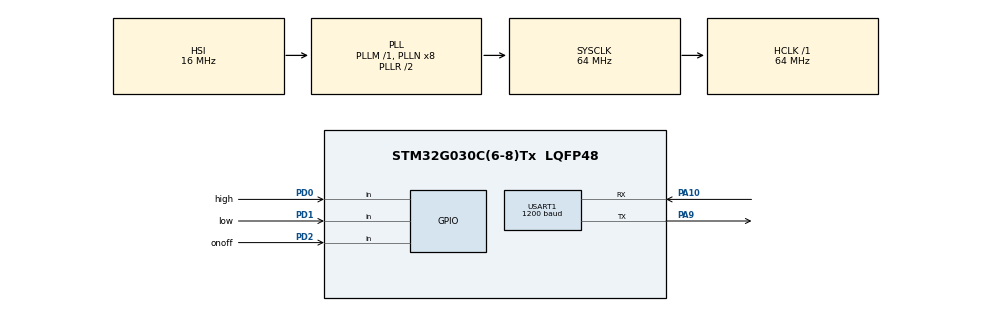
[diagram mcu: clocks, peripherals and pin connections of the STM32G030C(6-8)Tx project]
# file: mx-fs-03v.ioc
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Mcu.Family=STM32G0
Mcu.Name=STM32G030C(6-8)Tx
Mcu.Package=LQFP48
PA10.Mode=Asynchronous
PA10.Signal=USART1_RX
PA13.Mode=Serial_Wire
PA13.Signal=SYS_SWDIO
PA14-BOOT0.Mode=Serial_Wire
PA14-BOOT0.Signal=SYS_SWCLK
PA9.GPIO_Speed=GPIO_SPEED_FREQ_HIGH
PA9.Mode=Asynchronous
PA9.Signal=USART1_TX
PD0.GPIO_Label=high
PD0.GPIO_PuPd=GPIO_PULLUP
PD0.Signal=GPIO_Input
PD1.GPIO_Label=low
PD1.GPIO_PuPd=GPIO_PULLUP
PD1.Signal=GPIO_Input
PD2.GPIO_Label=onoff
PD2.GPIO_PuPd=GPIO_PULLUP
PD2.Signal=GPIO_Input
PF0-OSC_IN\ (PF0).Mode=HSE-External-Oscillator
PF0-OSC_IN\ (PF0).Signal=RCC_OSC_IN
PF1-OSC_OUT\ (PF1).Mode=HSE-External-Oscillator
PF1-OSC_OUT\ (PF1).Signal=RCC_OSC_OUT
ProjectManager.HeapSize=0x200
ProjectManager.StackSize=0x400
ProjectManager.TargetToolchain=MDK-ARM V5.32
RCC.ADCFreq_Value=64000000
RCC.AHBFreq_Value=64000000
RCC.CortexFreq_Value=64000000
RCC.EXTERNAL_CLOCK_VALUE=12288000
RCC.HCLKFreq_Value=64000000
RCC.HSE_VALUE=8000000
RCC.HSI_VALUE=16000000
RCC.LSE_VALUE=32768
RCC.SYSCLKFreq_VALUE=64000000
RCC.SYSCLKSource=RCC_SYSCLKSOURCE_PLLCLK
RCC.VCOOutputFreq_Value=128000000
TIM1.AutoReloadPreload=TIM_AUTORELOAD_PRELOAD_DISABLE
TIM1.Period=999
TIM1.Prescaler=31
USART1.BaudRate=1200
USART1.OneBitSampling=UART_ONE_BIT_SAMPLE_ENABLE
USART1.VirtualMode-Asynchronous=VM_ASYNC
VP_TIM1_VS_ClockSourceINT.Mode=Internal
board=custom

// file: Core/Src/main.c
/* USER CODE BEGIN Header */
/**
  ******************************************************************************
  * @file           : main.c
  * @brief          : Main program body
  ******************************************************************************
  * @attention
  *
  * Copyright (c) 2024 STMicroelectronics.
  * All rights reserved.
  *
  * This software is licensed under terms that can be found in the LICENSE file
  * in the root directory of this software component.
  * If no LICENSE file comes with this software, it is provided AS-IS.
  *
  ******************************************************************************
  */
/* USER CODE END Header */
#include "main.h"

 TIM_HandleTypeDef htim1;

 UART_HandleTypeDef huart1;

void SystemClock_Config(void);
static void MX_GPIO_Init(void);
static void MX_TIM1_Init(void);
static void MX_USART1_UART_Init(void);
/* USER CODE BEGIN PFP */
void send_command(uint8_t command);
/* USER CODE END PFP */

int main(void)
{

  /* MCU Configuration--------------------------------------------------------*/

  /* Reset of all peripherals, Initializes the Flash interface and the Systick. */
  HAL_Init();

  /* Configure the system clock */
  SystemClock_Config();

  /* Initialize all configured peripherals */
  MX_GPIO_Init();
  MX_TIM1_Init();
  MX_USART1_UART_Init();
  /* USER CODE BEGIN 2 */
	HAL_UART_Init(&huart1);
  /* USER CODE END 2 */

  /* Infinite loop */
  while (1)
  {

    /* USER CODE BEGIN 3 */
		if(HAL_GPIO_ReadPin(GPIOD,high_Pin)==0){
				send_command(0x01);
				HAL_Delay(50);
		}
		if(HAL_GPIO_ReadPin(GPIOD,low_Pin)==0){
				send_command(0x02);
				HAL_Delay(50);
		}
		if(HAL_GPIO_ReadPin(GPIOD,onoff_Pin)==0){
				send_command(0x03);
				HAL_Delay(50);
		}
  }
  /* USER CODE END 3 */
}

void SystemClock_Config(void)
{
  RCC_OscInitTypeDef RCC_OscInitStruct = {0};
  RCC_ClkInitTypeDef RCC_ClkInitStruct = {0};

  /** Configure the main internal regulator output voltage
  */
  HAL_PWREx_ControlVoltageScaling(PWR_REGULATOR_VOLTAGE_SCALE1);

  /** Initializes the RCC Oscillators according to the specified parameters
  * in the RCC_OscInitTypeDef structure.
  */
  RCC_OscInitStruct.OscillatorType = RCC_OSCILLATORTYPE_HSI;
  RCC_OscInitStruct.HSIState = RCC_HSI_ON;
  RCC_OscInitStruct.HSIDiv = RCC_HSI_DIV1;
  RCC_OscInitStruct.HSICalibrationValue = RCC_HSICALIBRATION_DEFAULT;
  RCC_OscInitStruct.PLL.PLLState = RCC_PLL_ON;
  RCC_OscInitStruct.PLL.PLLSource = RCC_PLLSOURCE_HSI;
  RCC_OscInitStruct.PLL.PLLM = RCC_PLLM_DIV1;
  RCC_OscInitStruct.PLL.PLLN = 8;
  RCC_OscInitStruct.PLL.PLLP = RCC_PLLP_DIV2;
  RCC_OscInitStruct.PLL.PLLR = RCC_PLLR_DIV2;
  if (HAL_RCC_OscConfig(&RCC_OscInitStruct) != HAL_OK)
  {
    Error_Handler();
  }

  /** Initializes the CPU, AHB and APB buses clocks
  */
  RCC_ClkInitStruct.ClockType = RCC_CLOCKTYPE_HCLK|RCC_CLOCKTYPE_SYSCLK
                              |RCC_CLOCKTYPE_PCLK1;
  RCC_ClkInitStruct.SYSCLKSource = RCC_SYSCLKSOURCE_PLLCLK;
  RCC_ClkInitStruct.AHBCLKDivider = RCC_SYSCLK_DIV1;
  RCC_ClkInitStruct.APB1CLKDivider = RCC_HCLK_DIV1;

  if (HAL_RCC_ClockConfig(&RCC_ClkInitStruct, FLASH_LATENCY_2) != HAL_OK)
  {
    Error_Handler();
  }
}

static void MX_TIM1_Init(void)
{

  TIM_ClockConfigTypeDef sClockSourceConfig = {0};
  TIM_MasterConfigTypeDef sMasterConfig = {0};

  htim1.Instance = TIM1;
  htim1.Init.Prescaler = 31;
  htim1.Init.CounterMode = TIM_COUNTERMODE_UP;
  htim1.Init.Period = 999;
  htim1.Init.ClockDivision = TIM_CLOCKDIVISION_DIV1;
  htim1.Init.RepetitionCounter = 0;
  htim1.Init.AutoReloadPreload = TIM_AUTORELOAD_PRELOAD_DISABLE;
  if (HAL_TIM_Base_Init(&htim1) != HAL_OK)
  {
    Error_Handler();
  }
  sClockSourceConfig.ClockSource = TIM_CLOCKSOURCE_INTERNAL;
  if (HAL_TIM_ConfigClockSource(&htim1, &sClockSourceConfig) != HAL_OK)
  {
    Error_Handler();
  }
  sMasterConfig.MasterOutputTrigger = TIM_TRGO_RESET;
  sMasterConfig.MasterOutputTrigger2 = TIM_TRGO2_RESET;
  sMasterConfig.MasterSlaveMode = TIM_MASTERSLAVEMODE_DISABLE;
  if (HAL_TIMEx_MasterConfigSynchronization(&htim1, &sMasterConfig) != HAL_OK)
  {
    Error_Handler();
  }

}

static void MX_USART1_UART_Init(void)
{

  huart1.Instance = USART1;
  huart1.Init.BaudRate = 1200;
  huart1.Init.WordLength = UART_WORDLENGTH_8B;
  huart1.Init.StopBits = UART_STOPBITS_1;
  huart1.Init.Parity = UART_PARITY_NONE;
  huart1.Init.Mode = UART_MODE_TX_RX;
  huart1.Init.HwFlowCtl = UART_HWCONTROL_NONE;
  huart1.Init.OverSampling = UART_OVERSAMPLING_16;
  huart1.Init.OneBitSampling = UART_ONE_BIT_SAMPLE_ENABLE;
  huart1.Init.ClockPrescaler = UART_PRESCALER_DIV1;
  huart1.AdvancedInit.AdvFeatureInit = UART_ADVFEATURE_NO_INIT;
  if (HAL_UART_Init(&huart1) != HAL_OK)
  {
    Error_Handler();
  }
  if (HAL_UARTEx_SetTxFifoThreshold(&huart1, UART_TXFIFO_THRESHOLD_1_8) != HAL_OK)
  {
    Error_Handler();
  }
  if (HAL_UARTEx_SetRxFifoThreshold(&huart1, UART_RXFIFO_THRESHOLD_1_8) != HAL_OK)
  {
    Error_Handler();
  }
  if (HAL_UARTEx_DisableFifoMode(&huart1) != HAL_OK)
  {
    Error_Handler();
  }

}

static void MX_GPIO_Init(void)
{
  GPIO_InitTypeDef GPIO_InitStruct = {0};

  /* GPIO Ports Clock Enable */
  __HAL_RCC_GPIOF_CLK_ENABLE();
  __HAL_RCC_GPIOA_CLK_ENABLE();
  __HAL_RCC_GPIOD_CLK_ENABLE();

  /*Configure GPIO pins : high_Pin low_Pin onoff_Pin */
  GPIO_InitStruct.Pin = high_Pin|low_Pin|onoff_Pin;
  GPIO_InitStruct.Mode = GPIO_MODE_INPUT;
  GPIO_InitStruct.Pull = GPIO_PULLUP;
  HAL_GPIO_Init(GPIOD, &GPIO_InitStruct);

}

/* USER CODE BEGIN 4 */
void send_command(uint8_t command){
	uint8_t frame[6]={0xAA,0xAA,0xAA,0x55,command,0xFF};
	HAL_UART_Transmit(&huart1,frame,sizeof(frame),HAL_MAX_DELAY);
}
/* USER CODE END 4 */

void Error_Handler(void)
{
  __disable_irq();
  while (1)
  {
  }
}
